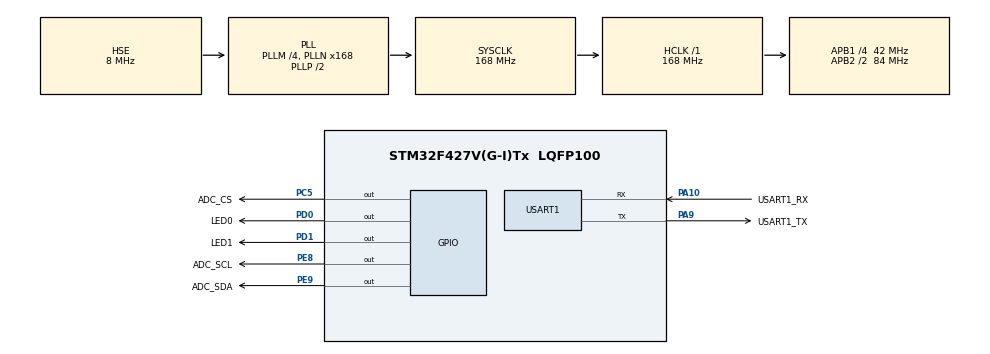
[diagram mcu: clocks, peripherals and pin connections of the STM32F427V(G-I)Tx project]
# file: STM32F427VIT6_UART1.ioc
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Mcu.Family=STM32F4
Mcu.Name=STM32F427V(G-I)Tx
Mcu.Package=LQFP100
NVIC.PriorityGroup=NVIC_PRIORITYGROUP_4
NVIC.USART1_IRQn=true\:0\:0\:false\:false\:true\:true
PA10.GPIO_Label=USART1_RX
PA10.Mode=Asynchronous
PA10.Signal=USART1_RX
PA9.GPIO_Label=USART1_TX
PA9.Mode=Asynchronous
PA9.Signal=USART1_TX
PC5.GPIO_Label=ADC_CS
PC5.GPIO_Speed=GPIO_SPEED_FREQ_HIGH
PC5.Signal=GPIO_Output
PD0.GPIO_Label=LED0
PD0.PinState=GPIO_PIN_SET
PD0.Signal=GPIO_Output
PD1.GPIO_Label=LED1
PD1.PinState=GPIO_PIN_SET
PD1.Signal=GPIO_Output
PE8.GPIO_Label=ADC_SCL
PE8.GPIO_Speed=GPIO_SPEED_FREQ_HIGH
PE8.Signal=GPIO_Output
PE9.GPIO_Label=ADC_SDA
PE9.GPIO_Speed=GPIO_SPEED_FREQ_HIGH
PE9.Signal=GPIO_Output
PH0/OSC_IN.Mode=HSE-External-Oscillator
PH0/OSC_IN.Signal=RCC_OSC_IN
PH1/OSC_OUT.Mode=HSE-External-Oscillator
PH1/OSC_OUT.Signal=RCC_OSC_OUT
ProjectManager.HeapSize=0x200
ProjectManager.StackSize=0x400
ProjectManager.TargetToolchain=MDK-ARM V5
RCC.48MHZClocksFreq_Value=84000000
RCC.AHBFreq_Value=168000000
RCC.APB1CLKDivider=RCC_HCLK_DIV4
RCC.APB1Freq_Value=42000000
RCC.APB1TimFreq_Value=84000000
RCC.APB2CLKDivider=RCC_HCLK_DIV2
RCC.APB2Freq_Value=84000000
RCC.APB2TimFreq_Value=168000000
RCC.CortexFreq_Value=168000000
RCC.HCLKFreq_Value=168000000
RCC.HSE_VALUE=8000000
RCC.HSI_VALUE=16000000
RCC.LSE_VALUE=32768
RCC.PLLM=4
RCC.PLLN=168
RCC.PLLSourceVirtual=RCC_PLLSOURCE_HSE
RCC.SYSCLKFreq_VALUE=168000000
RCC.SYSCLKSource=RCC_SYSCLKSOURCE_PLLCLK
RCC.VCOOutputFreq_Value=336000000
USART1.VirtualMode=VM_ASYNC
board=STM32F427VIT6_UART1

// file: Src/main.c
/**
  ******************************************************************************
  * File Name          : main.c
  * Description        : Main program body
  ******************************************************************************
  ** This notice applies to any and all portions of this file
  * that are not between comment pairs USER CODE BEGIN and
  * USER CODE END. Other portions of this file, whether
  * inserted by the user or by software development tools
  * are owned by their respective copyright owners.
  *
  * COPYRIGHT(c) 2018 STMicroelectronics
  *
  * Redistribution and use in source and binary forms, with or without modification,
  * are permitted provided that the following conditions are met:
  *   1. Redistributions of source code must retain the above copyright notice,
  *      this list of conditions and the following disclaimer.
  *   2. Redistributions in binary form must reproduce the above copyright notice,
  *      this list of conditions and the following disclaimer in the documentation
  *      and/or other materials provided with the distribution.
  *   3. Neither the name of STMicroelectronics nor the names of its contributors
  *      may be used to endorse or promote products derived from this software
  *      without specific prior written permission.
  *
  * THIS SOFTWARE IS PROVIDED BY THE COPYRIGHT HOLDERS AND CONTRIBUTORS "AS IS"
  * AND ANY EXPRESS OR IMPLIED WARRANTIES, INCLUDING, BUT NOT LIMITED TO, THE
  * IMPLIED WARRANTIES OF MERCHANTABILITY AND FITNESS FOR A PARTICULAR PURPOSE ARE
  * DISCLAIMED. IN NO EVENT SHALL THE COPYRIGHT HOLDER OR CONTRIBUTORS BE LIABLE
  * FOR ANY DIRECT, INDIRECT, INCIDENTAL, SPECIAL, EXEMPLARY, OR CONSEQUENTIAL
  * DAMAGES (INCLUDING, BUT NOT LIMITED TO, PROCUREMENT OF SUBSTITUTE GOODS OR
  * SERVICES; LOSS OF USE, DATA, OR PROFITS; OR BUSINESS INTERRUPTION) HOWEVER
  * CAUSED AND ON ANY THEORY OF LIABILITY, WHETHER IN CONTRACT, STRICT LIABILITY,
  * OR TORT (INCLUDING NEGLIGENCE OR OTHERWISE) ARISING IN ANY WAY OUT OF THE USE
  * OF THIS SOFTWARE, EVEN IF ADVISED OF THE POSSIBILITY OF SUCH DAMAGE.
  *
  ******************************************************************************
  */

#include "main.h"
#include "stm32f4xx_hal.h"
//#include "ads1115.h"
//#include "usart.h"

/* USER CODE BEGIN Includes */
#include "can.h"

/* USER CODE END Includes */
#define RXBUFFERSIZE   1 //缓存大小
#define EN_USART1_RX 			1			//使能（1）/禁止（0）串口1接收

UART_HandleTypeDef huart1;
u8 aRxBuffer[RXBUFFERSIZE];//HAL库使用的串口接收缓冲
UART_HandleTypeDef UART1_Handler; //UART句柄
/* USER CODE BEGIN PV */
/* Private variables ---------------------------------------------------------*/

/* USER CODE END PV */

void SystemClock_Config(void);
static void MX_GPIO_Init(void);
static void MX_USART1_UART_Init(void);
//void HAL_UART_MspInit(UART_HandleTypeDef *huart);

/* USER CODE BEGIN PFP */
/* Private function prototypes -----------------------------------------------*/

/* USER CODE END PFP */
/* USER CODE BEGIN 1 */
//printf重定义
#ifdef __GNUC__
  /* With GCC/RAISONANCE, small printf (option LD Linker->Libraries->Small printf
     set to 'Yes') calls __io_putchar() */
  #define PUTCHAR_PROTOTYPE int __io_putchar(int ch)
#else
  #define PUTCHAR_PROTOTYPE int fputc(int ch, FILE *f)
#endif /* __GNUC__ */
/**
  * @brief  Retargets the C library printf function to the USART.
  * @param  None
  * @retval None
  */
PUTCHAR_PROTOTYPE
{
  /* Place your implementation of fputc here */
  /* e.g. write a character to the EVAL_COM1 and Loop until the end of transmission */
  HAL_UART_Transmit(&huart1, (uint8_t *)&ch, 1, 0xFFFF);

  return ch;
}
/* USER CODE BEGIN 0 */

/* USER CODE END 0 */

int main(void)
{

  /* USER CODE BEGIN 1 */
	u16 VAL=0;
//	u8 count;
//	u16 Num[5];
//	float temp;
  /* USER CODE END 1 */

  /* MCU Configuration----------------------------------------------------------*/

  /* Reset of all peripherals, Initializes the Flash interface and the Systick. */
  HAL_Init();

  /* Configure the system clock */
  SystemClock_Config();

  /* Initialize all configured peripherals */
  MX_GPIO_Init();

  MX_USART1_UART_Init();

//	ADS1115_Init();

  /* Infinite loop */
  while (1)
  {
//		VAL=ReadAD_A();
//		printf("adc:0x%x\t\n",VAL);
//		printf("%d\n",aRxBuffer[0]);
//		VAL=getad_A();
//		printf("adc:%x\n",VAL);
		HAL_Delay(500);

		HAL_GPIO_TogglePin(GPIOD,GPIO_PIN_0);

  }

}

/** System Clock Configuration
*/
void SystemClock_Config(void)
{

  RCC_OscInitTypeDef RCC_OscInitStruct;
  RCC_ClkInitTypeDef RCC_ClkInitStruct;

    /**Configure the main internal regulator output voltage
    */
  __HAL_RCC_PWR_CLK_ENABLE();

  __HAL_PWR_VOLTAGESCALING_CONFIG(PWR_REGULATOR_VOLTAGE_SCALE1);

    /**Initializes the CPU, AHB and APB busses clocks
    */
  RCC_OscInitStruct.OscillatorType = RCC_OSCILLATORTYPE_HSE;
  RCC_OscInitStruct.HSEState = RCC_HSE_ON;
  RCC_OscInitStruct.PLL.PLLState = RCC_PLL_ON;
  RCC_OscInitStruct.PLL.PLLSource = RCC_PLLSOURCE_HSE;
  RCC_OscInitStruct.PLL.PLLM = 4;
  RCC_OscInitStruct.PLL.PLLN = 168;
  RCC_OscInitStruct.PLL.PLLP = RCC_PLLP_DIV2;
  RCC_OscInitStruct.PLL.PLLQ = 4;
  if (HAL_RCC_OscConfig(&RCC_OscInitStruct) != HAL_OK)
  {
    _Error_Handler(__FILE__, __LINE__);
  }

    /**Initializes the CPU, AHB and APB busses clocks
    */
  RCC_ClkInitStruct.ClockType = RCC_CLOCKTYPE_HCLK|RCC_CLOCKTYPE_SYSCLK
                              |RCC_CLOCKTYPE_PCLK1|RCC_CLOCKTYPE_PCLK2;
  RCC_ClkInitStruct.SYSCLKSource = RCC_SYSCLKSOURCE_PLLCLK;
  RCC_ClkInitStruct.AHBCLKDivider = RCC_SYSCLK_DIV1;
  RCC_ClkInitStruct.APB1CLKDivider = RCC_HCLK_DIV4;
  RCC_ClkInitStruct.APB2CLKDivider = RCC_HCLK_DIV2;

  if (HAL_RCC_ClockConfig(&RCC_ClkInitStruct, FLASH_LATENCY_5) != HAL_OK)
  {
    _Error_Handler(__FILE__, __LINE__);
  }

    /**Configure the Systick interrupt time
    */
  HAL_SYSTICK_Config(HAL_RCC_GetHCLKFreq()/1000);

    /**Configure the Systick
    */
  HAL_SYSTICK_CLKSourceConfig(SYSTICK_CLKSOURCE_HCLK);

  /* SysTick_IRQn interrupt configuration */
  HAL_NVIC_SetPriority(SysTick_IRQn, 0, 0);
}

/* USART1 init function */
static void MX_USART1_UART_Init(void)
{

  huart1.Instance = USART1;
  huart1.Init.BaudRate = 115200;
  huart1.Init.WordLength = UART_WORDLENGTH_8B;
  huart1.Init.StopBits = UART_STOPBITS_1;
  huart1.Init.Parity = UART_PARITY_NONE;
  huart1.Init.Mode = UART_MODE_TX_RX;
  huart1.Init.HwFlowCtl = UART_HWCONTROL_NONE;
  huart1.Init.OverSampling = UART_OVERSAMPLING_16;
  if (HAL_UART_Init(&huart1) != HAL_OK)
  {
    _Error_Handler(__FILE__, __LINE__);
  }
	HAL_UART_Receive_IT(&UART1_Handler, (u8 *)aRxBuffer, RXBUFFERSIZE);//该函数会开启接收中断：标志位UART_IT_RXNE，并且设置接收缓冲以及接收缓冲接收最大数据量
}

/** Configure pins as
        * Analog
        * Input
        * Output
        * EVENT_OUT
        * EXTI
*/
static void MX_GPIO_Init(void)
{

  GPIO_InitTypeDef GPIO_InitStruct;

  /* GPIO Ports Clock Enable */
  __HAL_RCC_GPIOH_CLK_ENABLE();
  __HAL_RCC_GPIOC_CLK_ENABLE();
  __HAL_RCC_GPIOE_CLK_ENABLE();
  __HAL_RCC_GPIOA_CLK_ENABLE();
  __HAL_RCC_GPIOD_CLK_ENABLE();

  /*Configure GPIO pin Output Level */
//  HAL_GPIO_WritePin(ADC_CS_GPIO_Port, ADC_CS_Pin, GPIO_PIN_RESET);
	HAL_GPIO_WritePin(ADC_CS_GPIO_Port, ADC_CS_Pin, GPIO_PIN_SET);
  /*Configure GPIO pin Output Level */
  HAL_GPIO_WritePin(GPIOE, ADC_SCL_Pin|ADC_SDA_Pin, GPIO_PIN_RESET);

  /*Configure GPIO pin Output Level */
  HAL_GPIO_WritePin(GPIOD, LED0_Pin|LED1_Pin, GPIO_PIN_RESET);

  /*Configure GPIO pin : ADC_CS_Pin */
  GPIO_InitStruct.Pin = ADC_CS_Pin;
  GPIO_InitStruct.Mode = GPIO_MODE_OUTPUT_PP;
  GPIO_InitStruct.Pull = GPIO_NOPULL;
  GPIO_InitStruct.Speed = GPIO_SPEED_FREQ_HIGH;
  HAL_GPIO_Init(ADC_CS_GPIO_Port, &GPIO_InitStruct);

  /*Configure GPIO pins : ADC_SCL_Pin ADC_SDA_Pin */
  GPIO_InitStruct.Pin = ADC_SCL_Pin|ADC_SDA_Pin;
  GPIO_InitStruct.Mode = GPIO_MODE_OUTPUT_PP;
  GPIO_InitStruct.Pull = GPIO_NOPULL;
  GPIO_InitStruct.Speed = GPIO_SPEED_FREQ_HIGH;
  HAL_GPIO_Init(GPIOE, &GPIO_InitStruct);

  /*Configure GPIO pins : LED0_Pin LED1_Pin */
  GPIO_InitStruct.Pin = LED0_Pin|LED1_Pin;
  GPIO_InitStruct.Mode = GPIO_MODE_OUTPUT_PP;
  GPIO_InitStruct.Pull = GPIO_NOPULL;
  GPIO_InitStruct.Speed = GPIO_SPEED_FREQ_LOW;
  HAL_GPIO_Init(GPIOD, &GPIO_InitStruct);

}

///* USER CODE BEGIN 4 */
//void HAL_UART_MspInit(UART_HandleTypeDef *huart)
//{
//    //GPIO端口设置
//	GPIO_InitTypeDef GPIO_Initure;
//
//	if(huart->Instance==USART1)//如果是串口1，进行串口1 MSP初始化
//	{
//		__HAL_RCC_GPIOA_CLK_ENABLE();			//使能GPIOA时钟
//		__HAL_RCC_USART1_CLK_ENABLE();			//使能USART1时钟
//
//		GPIO_Initure.Pin=GPIO_PIN_9;			//PA9
//		GPIO_Initure.Mode=GPIO_MODE_AF_PP;		//复用推挽输出
//		GPIO_Initure.Pull=GPIO_PULLUP;			//上拉
//		GPIO_Initure.Speed=GPIO_SPEED_FAST;		//高速
//		GPIO_Initure.Alternate=GPIO_AF7_USART1;	//复用为USART1
//		HAL_GPIO_Init(GPIOA,&GPIO_Initure);	   	//初始化PA9

//		GPIO_Initure.Pin=GPIO_PIN_10;			//PA10
//		HAL_GPIO_Init(GPIOA,&GPIO_Initure);	   	//初始化PA10
//
//#if EN_USART1_RX
//		HAL_NVIC_EnableIRQ(USART1_IRQn);		//使能USART1中断通道
//		HAL_NVIC_SetPriority(USART1_IRQn,3,3);	//抢占优先级3，子优先级3
//#endif
//	}

//}
/* USER CODE END 4 */

void _Error_Handler(char * file, int line)
{
  while(1)
  {
  }
}

/************************ (C) COPYRIGHT STMicroelectronics *****END OF FILE****/
